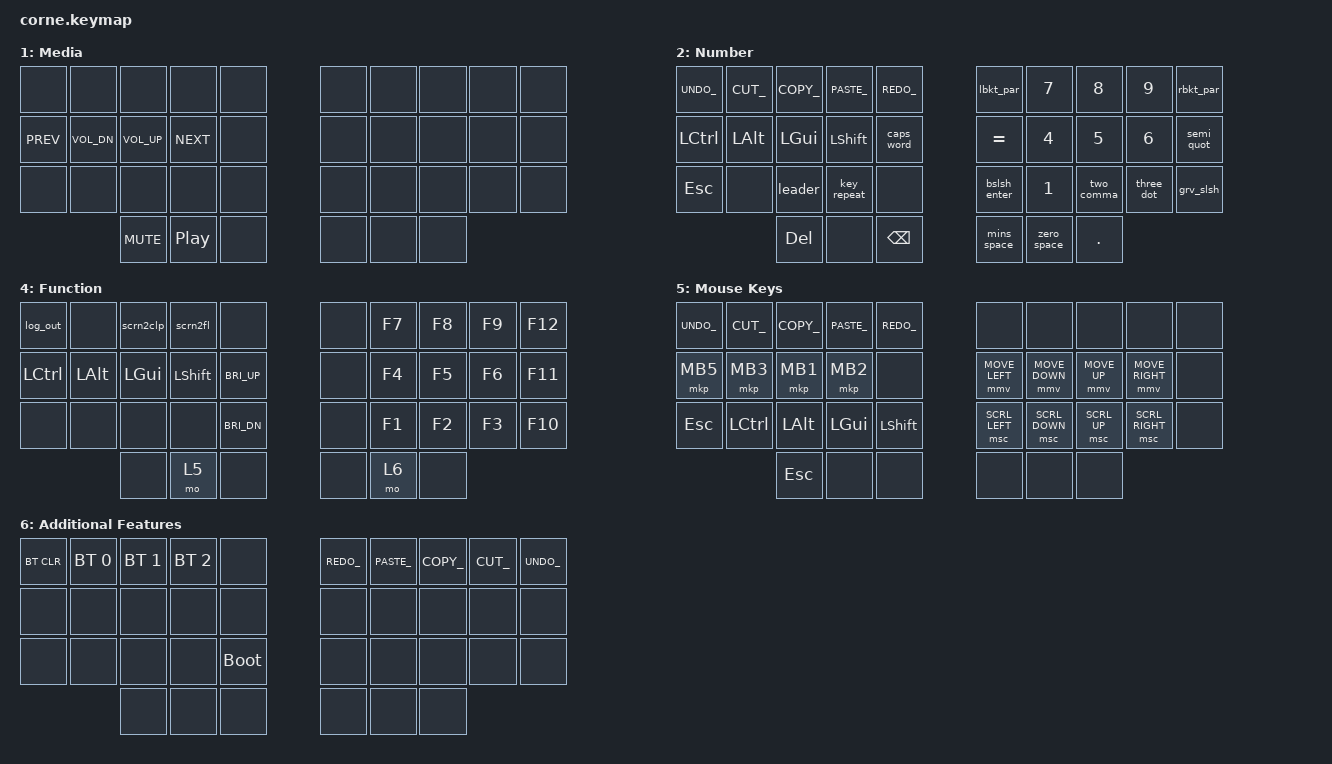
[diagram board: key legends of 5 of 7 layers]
/*
 * Copyright (c) 2020 The ZMK Contributors
 *
 * SPDX-License-Identifier: MIT
 */

#include <behaviors.dtsi>
#include <dt-bindings/zmk/keys.h>
#include <dt-bindings/zmk/bt.h>
#include <dt-bindings/zmk/pointing.h>
#include "aliases.h"

// hold-trigger-key-positions configs https://zmk.dev/docs/keymaps/behaviors/hold-tap?examples=home_row_mods#positional-hold-tap-and-hold-trigger-key-positions
#define KEYS_L 0 1 2 3 4  10 11 12 13 14  20 21 22 23 24
#define KEYS_R 5 6 7 8 9  15 16 17 18 19  25 26 27 28 29
#define THUMBS 30 31 32   33 34 35 // Corne
#include "behaviors.h"

/ {
    chosen {
        zmk,physical-layout = &foostan_corne_5col_layout;
    };
};

/ {
    keymap {
        compatible = "zmk,keymap";
        /*
          Layers
          0:  Base
          1:  Symbol/Media // in QMK NRM is in this position
          2:  Number
          3:  Navigation
          4:  Function
          5:  Mouse
          6:  Additional
         */
        base {
            display-name = "Base";
            bindings = <
            &kp Q      &kp W      &kp E      &kp R      &kp T                   &kp Y      &kp U      &kp I      &kp O      &kp P
            HRML(A,     S,         D,         F)        &kp G                   &kp H      HRMR(J,     K,         L,        SQT)
            &z_esc     &kp X       &kp C      &kp V      B_MEH                  N_MEH       &kp M     &cma_lprn &dot_rprn   &sls_ent
                               &lt 4 TAB  &lt 2 BSPC &lt 5 ESC                  &lt 5 RETURN &lt 3 SPACE &lt 1 DEL
            >;
        };

        med { // 1
            display-name = "Media";
            bindings = <
            &none      &none      &none      &none      &none                   &none      &none      &none      &none      &none
           &kp C_PREV &kp C_VOL_DN &kp C_VOL_UP &kp C_NEXT &none                   &none      &none      &none      &none      &none
            &none      &none      &none      &none      &none                   &none      &none      &none      &none      &none
                                        &kp C_MUTE &kp C_PP &none               &none &none &none
            >;
        };

        num { // 2
            display-name = "Number";
            bindings = <
            UNDO_     CUT_     COPY_    PASTE_      REDO_                    &lbkt_par   &kp N7      &kp N8      &kp N9   &rbkt_par
            &kp LCTRL &kp LALT &kp LGUI &kp LSHFT   &caps_word               &kp EQUAL  &kp N4     &kp N5     &kp N6     &semi_quot
            &kp ESC   &none    &leader  &key_repeat &none                &bslsh_enter &kp N1     &two_comma &three_dot &grv_slsh
                                           &kp DEL &none &kp BSPC               &mins_space &zero_space &kp DOT
            >;
        };

        nav { // 3
            display-name = "Navigation";
            bindings = <
            TAB_LFT   BACK      FWD       TAB_RGT     &up_dir                  REDO_      PASTE_      COPY_       CUT_        UNDO_
            &kp LCTRL &kp LALT  &kp LGUI  &kp LSHFT   &kp CAPS                &kp LEFT  &kp DOWN   &kp UP     &kp RIGHT  &kp SEMI
            &none     &none     &none     &key_repeat &none                  &kp HOME  &kp PG_DN  &kp PG_UP  &kp END    &kp RETURN
                                &none     &kp BSPC    &kp ENTER                &none &none      &none
            >;
        };

        fun { // 4
            display-name = "Function";
            bindings = <
            &log_out   &none      &scrn2clp  &scrn2fl   &none                    &none      &kp F7     &kp F8     &kp F9     &kp F12
            &kp LCTRL  &kp LALT   &kp LGUI  &kp LSHFT &kp C_BRI_UP               &none      &kp F4     &kp F5     &kp F6     &kp F11
            &none      &none      &none      &none     &kp C_BRI_DN              &none      &kp F1     &kp F2     &kp F3     &kp F10
                                             &none      &mo 5 &none              &none &mo 6      &none
            >;
        };

        mse { // 5
            display-name = "Mouse Keys";
            bindings = <
            UNDO_       CUT_        COPY_       PASTE_      REDO_                     &none      &none      &none      &none      &none
             &mkp MB5  &mkp MB3   &mkp MB1   &mkp MB2   &none                 &mmv MOVE_LEFT &mmv MOVE_DOWN &mmv MOVE_UP &mmv MOVE_RIGHT &none
            &kp ESC    &kp LCTRL  &kp LALT   &kp LGUI   &kp LSHFT             &msc SCRL_LEFT &msc SCRL_DOWN &msc SCRL_UP &msc SCRL_RIGHT &none
                                             &kp ESC &none &none              &none &none &none
            >;
        };

        add { // 6
            display-name = "Additional Features";
            bindings = <
          &bt BT_CLR &bt BT_SEL 0 &bt BT_SEL 1 &bt BT_SEL 2 &none                REDO_      PASTE_      COPY_       CUT_        UNDO_
            &none      &none      &none      &none      &none                    &none      &none      &none      &none      &none
            &none      &none      &none      &none      &bootloader             &none      &none      &none      &none      &none
                                             &none &none     &none              &none     &none       &none
            >;
        };
    };
};
